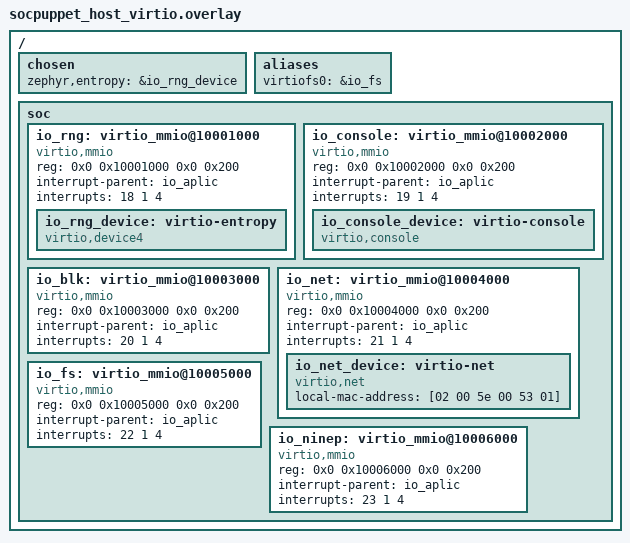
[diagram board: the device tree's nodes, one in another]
/ {
	chosen {
		zephyr,entropy = &io_rng_device;
	};

	aliases {
		virtiofs0 = &io_fs;
	};

	soc {
		io_rng: virtio_mmio@10001000 {
			compatible = "virtio,mmio";
			reg = <0x0 0x10001000 0x0 0x200>;
			interrupt-parent = <&io_aplic>;
			interrupts = <18 1 4>;
			io_rng_device: virtio-entropy {
				compatible = "virtio,device4";
			};
		};

		io_console: virtio_mmio@10002000 {
			compatible = "virtio,mmio";
			reg = <0x0 0x10002000 0x0 0x200>;
			interrupt-parent = <&io_aplic>;
			interrupts = <19 1 4>;
			io_console_device: virtio-console {
				compatible = "virtio,console";
			};
		};

		io_blk: virtio_mmio@10003000 {
			compatible = "virtio,mmio";
			reg = <0x0 0x10003000 0x0 0x200>;
			interrupt-parent = <&io_aplic>;
			interrupts = <20 1 4>;
		};

		io_net: virtio_mmio@10004000 {
			compatible = "virtio,mmio";
			reg = <0x0 0x10004000 0x0 0x200>;
			interrupt-parent = <&io_aplic>;
			interrupts = <21 1 4>;
			io_net_device: virtio-net {
				compatible = "virtio,net";
				local-mac-address = [02 00 5e 00 53 01];
			};
		};

		io_fs: virtio_mmio@10005000 {
			compatible = "virtio,mmio";
			reg = <0x0 0x10005000 0x0 0x200>;
			interrupt-parent = <&io_aplic>;
			interrupts = <22 1 4>;
		};

		io_ninep: virtio_mmio@10006000 {
			compatible = "virtio,mmio";
			reg = <0x0 0x10006000 0x0 0x200>;
			interrupt-parent = <&io_aplic>;
			interrupts = <23 1 4>;
		};
	};
};
